# STM32C532 register map
File version: 1.0.0
CPU: CM33 r0p4, little endian, MPU, FPU, 4 interrupt priority bits
Registers are 32-bit, read-write, reset 0x0 unless marked. A register's access mark holds for its fields unless they carry their own. Offsets are from the block's base; [hi:lo] are bit positions.

## SBS — SBS register block
Base 0x44000400
0x10 SBS_HDPLCR reset 0xB4 — SBS temporal isolation control register
  [7:0] INCR_HDPL — HDPL value increment
    180=No increment; 106=Recommended value to increment HDPL level by one
0x14 SBS_HDPLSR ro reset not defined — SBS temporal isolation status register
  [7:0] HDPL — Temporal isolation level
    81=HDPL1, hide protection level to be used to execute and protect an immutable root of trust (IROT) stage; 138=HDPL2, hide protection level to be used to execute and protect an updatable Root of Trust (UROT) stage; 111=HDPL3, hide protection level to be used to execute the application
0x18 SBS_NEXTTILCR — SBS next TIL control register
  [1:0] NEXTTIL — Next TIL control register
    0=OBK-TIL = TIL; 1=OBK-TIL = TIL + 1; 2=OBK-TIL = TIL + 2; 3=OBK-TIL = TIL + 3
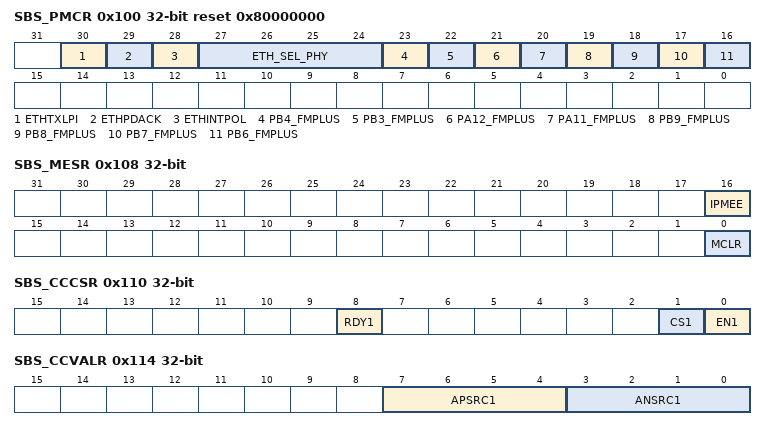
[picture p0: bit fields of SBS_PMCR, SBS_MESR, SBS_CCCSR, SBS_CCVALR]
0x100 SBS_PMCR reset 0x80000000 — SBS product mode and configuration register
  [30] ETHTXLPI ro — Ethernet TxLPI status
  [29] ETHPDACK ro — Ethernet power-down acknowledge
    0=Ethernet functional / power-down sequence not yet completed; 1=Ethernet power-down sequence completed
  [28] ETHINTPOL — Ethernet external PHY interrupt polarity configuration
    0=active high; 1=active low
  [27:24] ETH_SEL_PHY — Ethernet PHY interface selection
    0=GMII or MII; 4=RMII; 8=10BT1S
  [23] PB4_FMPLUS — Fast-mode Plus command on PB(4)
    0=Fast-mode Plus mode on PB(4) is disabled; 1=Fast-mode Plus mode on PB(4) is enabled
  [22] PB3_FMPLUS — Fast-mode Plus command on PB(3)
    0=Fast-mode Plus mode on PB(3) is disabled; 1=Fast-mode Plus mode on PB(3) is enabled
  [21] PA12_FMPLUS — Fast-mode Plus command on PA(12)
    0=Fast-mode Plus mode on PA(12) is disabled; 1=Fast-mode Plus mode on PA(12) is enabled
  [20] PA11_FMPLUS — Fast-mode Plus command on PA(11)
    0=Fast-mode Plus mode on PA(11) is disabled; 1=Fast-mode Plus mode on PA(11) is enabled
  [19] PB9_FMPLUS — Fast-mode Plus command on PB(9)
    0=Fast-mode Plus mode on PB(9) is disabled; 1=Fast-mode Plus mode on PB(9) is enabled
  [18] PB8_FMPLUS — Fast-mode Plus command on PB(8)
    0=Fast-mode Plus mode on PB(8) is disabled; 1=Fast-mode Plus mode on PB(8) is enabled
  [17] PB7_FMPLUS — Fast-mode Plus command on PB(7)
    0=Fast-mode Plus mode on PB(7) is disabled; 1=Fast mode plus mode on PB(7) is enabled
  [16] PB6_FMPLUS — Fast-mode Plus command on PB(6)
    0=Fast-mode Plus mode on PB(6) is disabled; 1=Fast-mode Plus mode on PB(6) is enabled
0x104 SBS_FPUIMR reset 0x1F — SBS FPU interrupt mask register
  [5:0] FPU_IE — FPU interrupt enable
0x108 SBS_MESR (reset mask 0xFFF0FFF0) — SBS memory erase status register
  [16] IPMEE — ICACHE erase status
    0=ICACHE erase ongoing; 1=ICACHE erase ended
  [0] MCLR — Device memories erase status
    0=Memory erase ongoing if not yet cleared by software; 1=Memory erase done
0x110 SBS_CCCSR — SBS compensation cell for I/Os control and status register
  [8] RDY1 ro — VDDIO compensation cell ready flag
    0=VDDIO compensation cell not ready; 1=VDDIO compensation cell ready (code value provided by the cell can be used)
  [1] CS1 — Code selection for VDDIO power rail (reset value set to 1)
    0=Code from the cell (available in the SBS_CCVR); 1=Code from SBS_CCCR
  [0] EN1 — Enable compensation cell for VDDIO power rail
    0=I/O compensation cell disabled; 1=I/O compensation cell enabled
0x114 SBS_CCVALR ro (reset mask 0xFFFFFF00) — SBS compensation cell for I/Os value register
  [7:4] APSRC1 — Compensation value for the PMOS transistor
  [3:0] ANSRC1 — Compensation value for the NMOS transistor
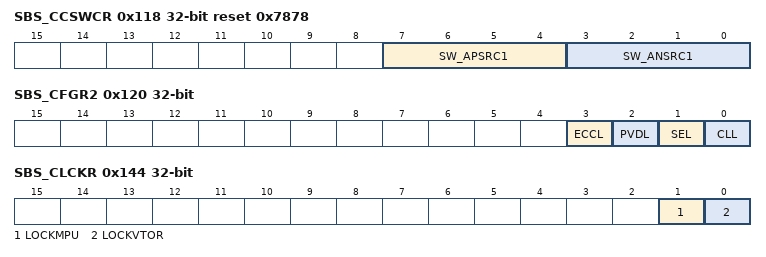
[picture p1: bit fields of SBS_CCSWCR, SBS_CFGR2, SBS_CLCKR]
0x118 SBS_CCSWCR reset 0x7878 — SBS compensation cell for I/Os software code register
  [7:4] SW_APSRC1 — PMOS compensation code for the VDD power rails
  [3:0] SW_ANSRC1 — NMOS compensation code for VDD power rails
0x120 SBS_CFGR2 — SBS Class B register
  [3] ECCL — ECC lock
    0=Double ECC error flag disconnected to timer break inputs; 1=Double ECC error flag connected to timer break inputs
  [2] PVDL — PVD lock
    0=PVD interrupt disconnected from timer break inputs; 1=PVD interrupt is connected to timer break inputs
  [1] SEL — SRAM ECC error lock
    0=SRAM double ECC error flag disconnected from timer break inputs; 1=SRAM double ECC error flag connected to timer break inputs
  [0] CLL — Core lockup lock
    0=Lockup output disconnected from timer break inputs; 1=Lockup output connected to timer break inputs
0x144 SBS_CLCKR — SBS CPU lock register
  [1] LOCKMPU — MPU register lock
    0=MPU registers write enabled; 1=MPU registers write disabled
  [0] LOCKVTOR — VTOR register lock
    0=VTOR register write enabled; 1=VTOR register write disabled
0x14C SBS_ECCNMIR — SBS ECC NMI mask register
  [0] ECCNMI_MASK_EN — NMI behavior setup when a double ECC error occurs on FLITF data part
    0=NMI generated if a double ECC error in the FLITF data part; 1=NMI not generated if a double ECC error in the FLITF data part

## Notices in the file
Copyright (c) 2026 STMicroelectronics.
SPDX-License-Identifier: Apache-2.0
Licensed under the Apache License, Version 2.0 (the "License");
you may not use this file except in compliance with the License.
You may obtain a copy of the License at
http://www.apache.org/licenses/LICENSE-2.0
Unless required by applicable law or agreed to in writing, software
distributed under the License is distributed on an "AS IS" BASIS,
WITHOUT WARRANTIES OR CONDITIONS OF ANY KIND, either express or implied.
See the License for the specific language governing permissions and
limitations under the License.
